# MKE15D7 register map
File version: 1.6
Registers are 32-bit, read-write, reset 0x0 unless marked. A register's access mark holds for its fields unless they carry their own. Offsets are from the block's base; [hi:lo] are bit positions; {n}, {i} and the like mark numbered series.

## OSC — Oscillator
Base 0x40045000; register names take the prefix OSC_
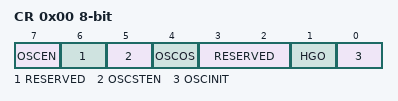
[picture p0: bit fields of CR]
0x00 CR 8-bit — OSC Control Register
  [7] OSCEN — OSC Enable
    0=OSC module disabled; 1=OSC module enabled
  [6] RESERVED ro
  [5] OSCSTEN — OSC Enable in Stop mode
    0=OSC clock is disabled in stop; 1=OSC clock stays enabled in stop
  [4] OSCOS — OSC Output Select
    0=External clock source from EXTAL pin is selected; 1=Oscillator clock source is selected
  [3:2] RESERVED ro
  [1] HGO — High Gain Oscillator Select
    0=Low power mode; 1=High gain mode
  [0] OSCINIT ro — OSC Initialization
    0=Oscillator initialization not completes; 1=Oscillator initialization completed

## PMC — Power management
Base 0x40054000; register names take the prefix PMC_
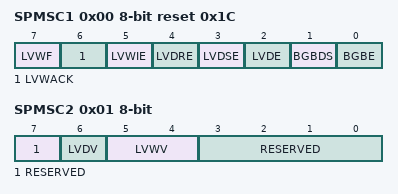
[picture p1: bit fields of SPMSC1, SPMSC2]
0x00 SPMSC1 8-bit reset 0x1C — System Power Management Status and Control 1 Register
  [7] LVWF ro — Low-Voltage Warning Flag
    0=Low-voltage warning is not present; 1=Low-voltage warning is present or was present
  [6] LVWACK wo — Low-Voltage Warning Acknowledge
  [5] LVWIE — Low-Voltage Warning Interrupt Enable
    0=Hardware interrupt disabled (use polling); 1=Request a hardware interrupt when LVWF = 1
  [4] LVDRE — Low-Voltage Detect Reset Enable
    0=LVD events do not generate hardware resets; 1=Force an MCU reset when an enabled low-voltage detect event occurs
  [3] LVDSE — Low-Voltage Detect Stop Enable
    0=Low-voltage detect disabled during stop mode; 1=Low-voltage detect enabled during stop mode
  [2] LVDE — Low-Voltage Detect Enable
    0=LVD logic disabled; 1=LVD logic enabled
  [1] BGBDS — Bandgap Buffer Drive Select
    0=Bandgap buffer enabled in low drive mode if BGBE = 1; 1=Bandgap buffer enabled in high drive mode if BGBE = 1
  [0] BGBE — Bandgap Buffer Enable
    0=Bandgap buffer disabled; 1=Bandgap buffer enabled
0x01 SPMSC2 8-bit — System Power Management Status and Control 2 Register
  [7] RESERVED ro
  [6] LVDV — Low-Voltage Detect Voltage Select
    0=Low trip point selected (VLVD = VLVDL); 1=High trip point selected (VLVD = VLVDH)
  [5:4] LVWV — Low-Voltage Warning Voltage Select
    0=Low trip point selected (VLVW = VLVW1); 1=Middle 1 trip point selected (VLVW = VLVW2); 2=Middle 2 trip point selected (VLVW = VLVW3); 3=High trip point selected (VLVW = VLVW4)
  [3:0] RESERVED ro

## SMC — System mode controller
Base 0x40056000; register names take the prefix SMC_
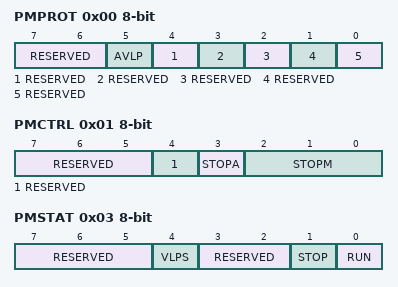
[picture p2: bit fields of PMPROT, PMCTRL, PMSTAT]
0x00 PMPROT 8-bit — SMC Power Mode Protection Register
  [7:6] RESERVED ro
  [5] AVLP — Allow Very Low Power Stop Mode
    0=VLPS is not allowed; 1=VLPS is allowed
  [4] RESERVED ro
  [3] RESERVED ro
  [2] RESERVED ro
  [1] RESERVED ro
  [0] RESERVED ro
0x01 PMCTRL 8-bit — SMC Power Mode Control Register
  [7:5] RESERVED ro
  [4] RESERVED ro
  [3] STOPA ro — Stop Aborted
    0=The previous stop mode entry was successsful; 1=The previous stop mode entry was aborted
  [2:0] STOPM — Stop Mode Control
    0=STOP; 2=VLPS
0x03 PMSTAT 8-bit ro — SMC Power Mode Status Register
  [7:5] RESERVED
  [4] VLPS — Current Power mode is VLPS
    0=Current Power mode is not VLPS; 1=Current Power mode is VLPS
  [3:2] RESERVED
  [1] STOP — Current Power mode is STOP
    0=Current Power mode is not stop; 1=Current Power mode is stop
  [0] RUN — CurrCurrent Power mode is run
    0=Current Power mode is not run; 1=Current Power mode is run

## RCM — Reset control module
Base 0x40057000; register names take the prefix RCM_
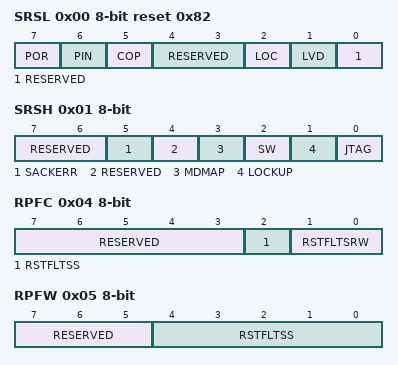
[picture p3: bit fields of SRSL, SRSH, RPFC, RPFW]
0x00 SRSL 8-bit ro reset 0x82 — RCM System Reset Status Low Register
  [7] POR — Power On Reset
    0=Reset not caused by POR; 1=Reset caused by POR
  [6] PIN — External RESETb Pin
    0=Reset not caused by external RESETb pin; 1=Reset caused by external RESETb pin
  [5] COP — COP Watchdog Reset
    0=Reset not caused by Watchdog Reset; 1=Reset caused by Watchdog Reset
  [4:3] RESERVED
  [2] LOC — Loss Of Clock Reset
    0=Reset not caused by Watchdog Reset; 1=Reset caused by loss of external clock
  [1] LVD — Low Voltage Detect
    0=Reset not caused by LVD trip or POR; 1=Reset caused by LVD trip or POR
  [0] RESERVED
0x01 SRSH 8-bit ro — RCM System Reset Status High Register
  [7:6] RESERVED
  [5] SACKERR — Stop Mode Acknowledge Error Reset
    0=Reset not caused by peripheral failure to acknowledge attempt to enter stop mode; 1=Reset caused by peripheral failure to acknowledge attempt to enter stop mode
  [4] RESERVED
  [3] MDMAP — MDM-AP system reset request
    0=Reset not caused by MDM-AP request; 1=Reset caused by MDM-AP request
  [2] SW — Software Reset
    0=Reset not caused by Software Reset; 1=Reset caused by Software Reset
  [1] LOCKUP — CPU LOCKUP Reset
    0=Reset not caused by CPU LOCKUP; 1=Reset caused by CPU LOCKUP
  [0] JTAG — JTAG Reset
    0=Reset not caused by JTAG; 1=Reset caused by JTAG
0x04 RPFC 8-bit — RCM RESETb Pin Filter Control Register
  [7:3] RESERVED ro
  [2] RSTFLTSS — Reset Pin Filter Select in Stop Modes
    0=All filtering disabled; 1=LPO clock filter enabled
  [1:0] RSTFLTSRW — Reset Pin Filter Select in Run and Wait Modes
    0=All filtering disabled; 1=Bus Clock filter enabled; 2=LPO clock filter enabled; 3=All filtering disabled
0x05 RPFW 8-bit — RCM RESETb Pin Filter Width Register
  [7:5] RESERVED ro
  [4:0] RSTFLTSS — RESETb Pin bus clock filter width
    {v}=Bus Clock Filter Width is {v+1} (v=0..31)
